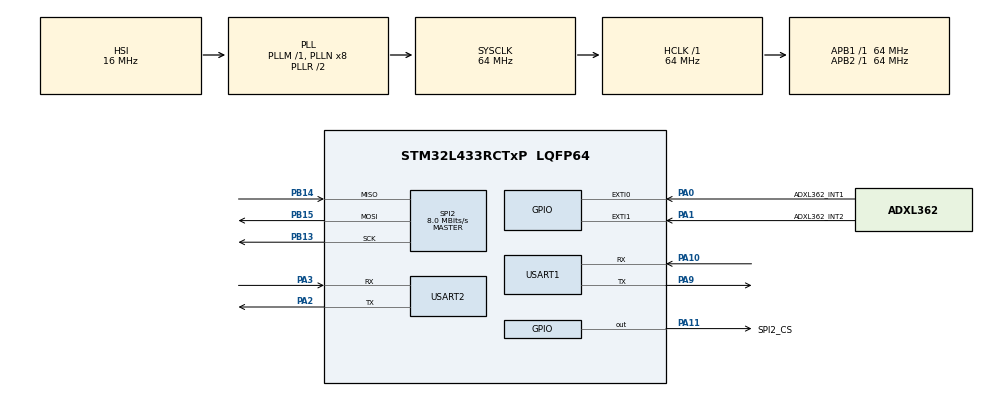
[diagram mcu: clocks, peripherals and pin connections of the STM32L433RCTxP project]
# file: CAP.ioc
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Dma.Request0=SPI2_TX
Dma.Request1=SPI2_RX
Dma.Request2=USART2_RX
Dma.Request3=USART2_TX
Dma.Request4=USART1_RX
Dma.Request5=USART1_TX
Dma.SPI2_RX.1.Direction=DMA_PERIPH_TO_MEMORY
Dma.SPI2_RX.1.Instance=DMA1_Channel4
Dma.SPI2_RX.1.MemDataAlignment=DMA_MDATAALIGN_BYTE
Dma.SPI2_RX.1.MemInc=DMA_MINC_ENABLE
Dma.SPI2_RX.1.Mode=DMA_NORMAL
Dma.SPI2_RX.1.PeriphDataAlignment=DMA_PDATAALIGN_BYTE
Dma.SPI2_RX.1.PeriphInc=DMA_PINC_DISABLE
Dma.SPI2_RX.1.Priority=DMA_PRIORITY_LOW
Dma.SPI2_TX.0.Direction=DMA_MEMORY_TO_PERIPH
Dma.SPI2_TX.0.Instance=DMA1_Channel5
Dma.SPI2_TX.0.MemDataAlignment=DMA_MDATAALIGN_BYTE
Dma.SPI2_TX.0.MemInc=DMA_MINC_ENABLE
Dma.SPI2_TX.0.Mode=DMA_NORMAL
Dma.SPI2_TX.0.PeriphDataAlignment=DMA_PDATAALIGN_BYTE
Dma.SPI2_TX.0.PeriphInc=DMA_PINC_DISABLE
Dma.SPI2_TX.0.Priority=DMA_PRIORITY_LOW
Dma.USART1_RX.4.Direction=DMA_PERIPH_TO_MEMORY
Dma.USART1_RX.4.Instance=DMA2_Channel7
Dma.USART1_RX.4.MemDataAlignment=DMA_MDATAALIGN_BYTE
Dma.USART1_RX.4.MemInc=DMA_MINC_ENABLE
Dma.USART1_RX.4.Mode=DMA_NORMAL
Dma.USART1_RX.4.PeriphDataAlignment=DMA_PDATAALIGN_BYTE
Dma.USART1_RX.4.PeriphInc=DMA_PINC_DISABLE
Dma.USART1_RX.4.Priority=DMA_PRIORITY_LOW
Dma.USART1_TX.5.Direction=DMA_MEMORY_TO_PERIPH
Dma.USART1_TX.5.Instance=DMA2_Channel6
Dma.USART1_TX.5.MemDataAlignment=DMA_MDATAALIGN_BYTE
Dma.USART1_TX.5.MemInc=DMA_MINC_ENABLE
Dma.USART1_TX.5.Mode=DMA_NORMAL
Dma.USART1_TX.5.PeriphDataAlignment=DMA_PDATAALIGN_BYTE
Dma.USART1_TX.5.PeriphInc=DMA_PINC_DISABLE
Dma.USART1_TX.5.Priority=DMA_PRIORITY_LOW
Dma.USART2_RX.2.Direction=DMA_PERIPH_TO_MEMORY
Dma.USART2_RX.2.Instance=DMA1_Channel6
Dma.USART2_RX.2.MemDataAlignment=DMA_MDATAALIGN_BYTE
Dma.USART2_RX.2.MemInc=DMA_MINC_ENABLE
Dma.USART2_RX.2.Mode=DMA_CIRCULAR
Dma.USART2_RX.2.PeriphDataAlignment=DMA_PDATAALIGN_BYTE
Dma.USART2_RX.2.PeriphInc=DMA_PINC_DISABLE
Dma.USART2_RX.2.Priority=DMA_PRIORITY_LOW
Dma.USART2_TX.3.Direction=DMA_MEMORY_TO_PERIPH
Dma.USART2_TX.3.Instance=DMA1_Channel7
Dma.USART2_TX.3.MemDataAlignment=DMA_MDATAALIGN_BYTE
Dma.USART2_TX.3.MemInc=DMA_MINC_ENABLE
Dma.USART2_TX.3.Mode=DMA_CIRCULAR
Dma.USART2_TX.3.PeriphDataAlignment=DMA_PDATAALIGN_BYTE
Dma.USART2_TX.3.PeriphInc=DMA_PINC_DISABLE
Dma.USART2_TX.3.Priority=DMA_PRIORITY_LOW
Mcu.Family=STM32L4
Mcu.Name=STM32L433RCTxP
Mcu.Package=LQFP64
NVIC.DMA1_Channel4_IRQn=true\:0\:0\:false\:false\:true\:false\:true
NVIC.DMA1_Channel5_IRQn=true\:0\:0\:false\:false\:true\:false\:true
NVIC.DMA1_Channel6_IRQn=true\:0\:0\:false\:false\:true\:false\:true
NVIC.DMA1_Channel7_IRQn=true\:0\:0\:false\:false\:true\:false\:true
NVIC.DMA2_Channel6_IRQn=true\:0\:0\:false\:false\:true\:false\:true
NVIC.DMA2_Channel7_IRQn=true\:0\:0\:false\:false\:true\:false\:true
NVIC.EXTI0_IRQn=true\:0\:0\:false\:false\:true\:true\:true
NVIC.EXTI1_IRQn=true\:0\:0\:false\:false\:true\:true\:true
NVIC.PriorityGroup=NVIC_PRIORITYGROUP_4
PA0.GPIO_Label=ADXL362_INT1
PA0.Signal=GPXTI0
PA1.GPIO_Label=ADXL362_INT2
PA1.Signal=GPXTI1
PA10.Mode=Asynchronous
PA10.Signal=USART1_RX
PA11.GPIO_Label=SPI2_CS
PA11.GPIO_Speed=GPIO_SPEED_FREQ_VERY_HIGH
PA11.PinState=GPIO_PIN_SET
PA11.Signal=GPIO_Output
PA13\ (JTMS-SWDIO).Mode=Serial_Wire
PA13\ (JTMS-SWDIO).Signal=SYS_JTMS-SWDIO
PA14\ (JTCK-SWCLK).Mode=Serial_Wire
PA14\ (JTCK-SWCLK).Signal=SYS_JTCK-SWCLK
PA2.Mode=Asynchronous
PA2.Signal=USART2_TX
PA3.Mode=Asynchronous
PA3.Signal=USART2_RX
PA9.Mode=Asynchronous
PA9.Signal=USART1_TX
PB13.Mode=Full_Duplex_Master
PB13.Signal=SPI2_SCK
PB14.Mode=Full_Duplex_Master
PB14.Signal=SPI2_MISO
PB15.Mode=Full_Duplex_Master
PB15.Signal=SPI2_MOSI
ProjectManager.HeapSize=0x200
ProjectManager.StackSize=0x400
ProjectManager.TargetToolchain=SW4STM32
RCC.ADCFreq_Value=64000000
RCC.AHBFreq_Value=64000000
RCC.APB1Freq_Value=64000000
RCC.APB1TimFreq_Value=64000000
RCC.APB2Freq_Value=64000000
RCC.APB2TimFreq_Value=64000000
RCC.CortexFreq_Value=64000000
RCC.HCLKFreq_Value=64000000
RCC.HSE_VALUE=8000000
RCC.HSI48_VALUE=48000000
RCC.HSI_VALUE=16000000
RCC.LSE_VALUE=32768
RCC.MSI_VALUE=4000000
RCC.PLLSourceVirtual=RCC_PLLSOURCE_HSI
RCC.PREFETCH_ENABLE=1
RCC.SYSCLKFreq_VALUE=64000000
RCC.SYSCLKSource=RCC_SYSCLKSOURCE_PLLCLK
RCC.USBFreq_Value=64000000
RCC.VCOOutputFreq_Value=128000000
SPI2.BaudRatePrescaler=SPI_BAUDRATEPRESCALER_8
SPI2.CalculateBaudRate=8.0 MBits/s
SPI2.DataSize=SPI_DATASIZE_8BIT
SPI2.Direction=SPI_DIRECTION_2LINES
SPI2.Mode=SPI_MODE_MASTER
SPI2.VirtualType=VM_MASTER
USART1.VirtualMode-Asynchronous=VM_ASYNC
USART2.VirtualMode-Asynchronous=VM_ASYNC
board=NUCLEO-L433RC-P

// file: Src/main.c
/* USER CODE BEGIN Header */
/**
  ******************************************************************************
  * @file           : main.c
  * @brief          : Main program body
  ******************************************************************************
  * @attention
  *
  * <h2><center>&copy; Copyright (c) 2019 STMicroelectronics.
  * All rights reserved.</center></h2>
  *
  * This software component is licensed by ST under BSD 3-Clause license,
  * the "License"; You may not use this file except in compliance with the
  * License. You may obtain a copy of the License at:
  *                        opensource.org/licenses/BSD-3-Clause
  *
  ******************************************************************************
  */
/* USER CODE END Header */

#include "main.h"

/* USER CODE BEGIN Includes */
#include "ADXL362.h"
/* USER CODE END Includes */

SPI_HandleTypeDef hspi2;
DMA_HandleTypeDef hdma_spi2_tx;
DMA_HandleTypeDef hdma_spi2_rx;

UART_HandleTypeDef huart1;
UART_HandleTypeDef huart2;
DMA_HandleTypeDef hdma_usart1_rx;
DMA_HandleTypeDef hdma_usart1_tx;
DMA_HandleTypeDef hdma_usart2_rx;
DMA_HandleTypeDef hdma_usart2_tx;

/* USER CODE BEGIN PV */
int8_t x8 = 0, y8 = 0, z8 = 0, temp8 = 0;
int16_t x12 = 0, y12 = 0, z12 = 0, temp12 = 0;
volatile uint32_t drFlag, GarageState;
//float xg, yg, zg;
char message[100];
/* USER CODE END PV */

void SystemClock_Config(void);
static void MX_GPIO_Init(void);
static void MX_DMA_Init(void);
static void MX_SPI2_Init(void);
static void MX_USART2_UART_Init(void);
static void MX_USART1_UART_Init(void);
/* USER CODE BEGIN PFP */
void HAL_SPI_TxRxCpltCallback(SPI_HandleTypeDef *hspi);
void HAL_GPIO_EXTI_Callback(uint16_t GPIO_Pin);
/* USER CODE END PFP */

/* USER CODE BEGIN 0 */
void HAL_SPI_TxRxCpltCallback(SPI_HandleTypeDef *hspi)
{
	if(hspi->Instance==SPI2)
	{
	}
}

void HAL_GPIO_EXTI_Callback(uint16_t GPIO_Pin)
{
	if(GPIO_Pin == ADXL362_INT1_Pin)
	{
		drFlag = 12;
	}
}

/* USER CODE END 0 */

int main(void)
{

  /* MCU Configuration--------------------------------------------------------*/

  /* Reset of all peripherals, Initializes the Flash interface and the Systick. */
  HAL_Init();

  /* Configure the system clock */
  SystemClock_Config();

  /* Initialize all configured peripherals */
  MX_GPIO_Init();
  MX_DMA_Init();
  MX_SPI2_Init();
  MX_USART2_UART_Init();
  MX_USART1_UART_Init();
  /* USER CODE BEGIN 2 */
  ADXL362_Init();
  /* USER CODE END 2 */

  /* Infinite loop */
  /* USER CODE BEGIN WHILE */
  while (1)
  {
	  if(drFlag == 8)
	  {
		  drFlag = 0;
		  ADXL362_GetXYZ8(&x8, &y8, &z8);
		  sprintf(message, "x = %+04d, y = %+04d, z = %+04d\r\n", x8, y8, z8);
		  HAL_UART_Transmit(&huart2, (uint8_t*)message, strlen(message), 0xFFFF);
	  }

	  else if(drFlag == 12)
	  {
		  drFlag = 0;
		  ADXL362_GetXYZT12(&x12, &y12, &z12, &temp12);
		  sprintf(message, "x = %+05d, y = %+05d, z = %+05d, temp = %+05d\r\n", x12, y12, z12, temp12);
		  //sprintf(message, "%04X, %04X, %04X\r\n", x12, y12, z12);
		  HAL_UART_Transmit(&huart2, (uint8_t*)message, strlen(message), 0xFFFF);
	  }
    /* USER CODE END WHILE */

  }
}

void SystemClock_Config(void)
{
  RCC_OscInitTypeDef RCC_OscInitStruct = {0};
  RCC_ClkInitTypeDef RCC_ClkInitStruct = {0};
  RCC_PeriphCLKInitTypeDef PeriphClkInit = {0};

  /** Initializes the CPU, AHB and APB busses clocks
  */
  RCC_OscInitStruct.OscillatorType = RCC_OSCILLATORTYPE_HSI;
  RCC_OscInitStruct.HSIState = RCC_HSI_ON;
  RCC_OscInitStruct.HSICalibrationValue = RCC_HSICALIBRATION_DEFAULT;
  RCC_OscInitStruct.PLL.PLLState = RCC_PLL_ON;
  RCC_OscInitStruct.PLL.PLLSource = RCC_PLLSOURCE_HSI;
  RCC_OscInitStruct.PLL.PLLM = 1;
  RCC_OscInitStruct.PLL.PLLN = 8;
  RCC_OscInitStruct.PLL.PLLP = RCC_PLLP_DIV7;
  RCC_OscInitStruct.PLL.PLLQ = RCC_PLLQ_DIV2;
  RCC_OscInitStruct.PLL.PLLR = RCC_PLLR_DIV2;
  if (HAL_RCC_OscConfig(&RCC_OscInitStruct) != HAL_OK)
  {
    Error_Handler();
  }
  /** Initializes the CPU, AHB and APB busses clocks
  */
  RCC_ClkInitStruct.ClockType = RCC_CLOCKTYPE_HCLK|RCC_CLOCKTYPE_SYSCLK
                              |RCC_CLOCKTYPE_PCLK1|RCC_CLOCKTYPE_PCLK2;
  RCC_ClkInitStruct.SYSCLKSource = RCC_SYSCLKSOURCE_PLLCLK;
  RCC_ClkInitStruct.AHBCLKDivider = RCC_SYSCLK_DIV1;
  RCC_ClkInitStruct.APB1CLKDivider = RCC_HCLK_DIV1;
  RCC_ClkInitStruct.APB2CLKDivider = RCC_HCLK_DIV1;

  if (HAL_RCC_ClockConfig(&RCC_ClkInitStruct, FLASH_LATENCY_3) != HAL_OK)
  {
    Error_Handler();
  }
  PeriphClkInit.PeriphClockSelection = RCC_PERIPHCLK_USART1|RCC_PERIPHCLK_USART2;
  PeriphClkInit.Usart1ClockSelection = RCC_USART1CLKSOURCE_PCLK2;
  PeriphClkInit.Usart2ClockSelection = RCC_USART2CLKSOURCE_PCLK1;
  if (HAL_RCCEx_PeriphCLKConfig(&PeriphClkInit) != HAL_OK)
  {
    Error_Handler();
  }
  /** Configure the main internal regulator output voltage
  */
  if (HAL_PWREx_ControlVoltageScaling(PWR_REGULATOR_VOLTAGE_SCALE1) != HAL_OK)
  {
    Error_Handler();
  }
}

static void MX_SPI2_Init(void)
{

  /* SPI2 parameter configuration*/
  hspi2.Instance = SPI2;
  hspi2.Init.Mode = SPI_MODE_MASTER;
  hspi2.Init.Direction = SPI_DIRECTION_2LINES;
  hspi2.Init.DataSize = SPI_DATASIZE_8BIT;
  hspi2.Init.CLKPolarity = SPI_POLARITY_LOW;
  hspi2.Init.CLKPhase = SPI_PHASE_1EDGE;
  hspi2.Init.NSS = SPI_NSS_SOFT;
  hspi2.Init.BaudRatePrescaler = SPI_BAUDRATEPRESCALER_8;
  hspi2.Init.FirstBit = SPI_FIRSTBIT_MSB;
  hspi2.Init.TIMode = SPI_TIMODE_DISABLE;
  hspi2.Init.CRCCalculation = SPI_CRCCALCULATION_DISABLE;
  hspi2.Init.CRCPolynomial = 7;
  hspi2.Init.CRCLength = SPI_CRC_LENGTH_DATASIZE;
  hspi2.Init.NSSPMode = SPI_NSS_PULSE_ENABLE;
  if (HAL_SPI_Init(&hspi2) != HAL_OK)
  {
    Error_Handler();
  }

}

static void MX_USART1_UART_Init(void)
{

  huart1.Instance = USART1;
  huart1.Init.BaudRate = 115200;
  huart1.Init.WordLength = UART_WORDLENGTH_8B;
  huart1.Init.StopBits = UART_STOPBITS_1;
  huart1.Init.Parity = UART_PARITY_NONE;
  huart1.Init.Mode = UART_MODE_TX_RX;
  huart1.Init.HwFlowCtl = UART_HWCONTROL_NONE;
  huart1.Init.OverSampling = UART_OVERSAMPLING_16;
  huart1.Init.OneBitSampling = UART_ONE_BIT_SAMPLE_DISABLE;
  huart1.AdvancedInit.AdvFeatureInit = UART_ADVFEATURE_NO_INIT;
  if (HAL_UART_Init(&huart1) != HAL_OK)
  {
    Error_Handler();
  }

}

static void MX_USART2_UART_Init(void)
{

  huart2.Instance = USART2;
  huart2.Init.BaudRate = 115200;
  huart2.Init.WordLength = UART_WORDLENGTH_8B;
  huart2.Init.StopBits = UART_STOPBITS_1;
  huart2.Init.Parity = UART_PARITY_NONE;
  huart2.Init.Mode = UART_MODE_TX_RX;
  huart2.Init.HwFlowCtl = UART_HWCONTROL_NONE;
  huart2.Init.OverSampling = UART_OVERSAMPLING_16;
  huart2.Init.OneBitSampling = UART_ONE_BIT_SAMPLE_DISABLE;
  huart2.AdvancedInit.AdvFeatureInit = UART_ADVFEATURE_NO_INIT;
  if (HAL_UART_Init(&huart2) != HAL_OK)
  {
    Error_Handler();
  }

}

static void MX_DMA_Init(void)
{

  /* DMA controller clock enable */
  __HAL_RCC_DMA1_CLK_ENABLE();
  __HAL_RCC_DMA2_CLK_ENABLE();

  /* DMA interrupt init */
  /* DMA1_Channel4_IRQn interrupt configuration */
  HAL_NVIC_SetPriority(DMA1_Channel4_IRQn, 0, 0);
  HAL_NVIC_EnableIRQ(DMA1_Channel4_IRQn);
  /* DMA1_Channel5_IRQn interrupt configuration */
  HAL_NVIC_SetPriority(DMA1_Channel5_IRQn, 0, 0);
  HAL_NVIC_EnableIRQ(DMA1_Channel5_IRQn);
  /* DMA1_Channel6_IRQn interrupt configuration */
  HAL_NVIC_SetPriority(DMA1_Channel6_IRQn, 0, 0);
  HAL_NVIC_EnableIRQ(DMA1_Channel6_IRQn);
  /* DMA1_Channel7_IRQn interrupt configuration */
  HAL_NVIC_SetPriority(DMA1_Channel7_IRQn, 0, 0);
  HAL_NVIC_EnableIRQ(DMA1_Channel7_IRQn);
  /* DMA2_Channel6_IRQn interrupt configuration */
  HAL_NVIC_SetPriority(DMA2_Channel6_IRQn, 0, 0);
  HAL_NVIC_EnableIRQ(DMA2_Channel6_IRQn);
  /* DMA2_Channel7_IRQn interrupt configuration */
  HAL_NVIC_SetPriority(DMA2_Channel7_IRQn, 0, 0);
  HAL_NVIC_EnableIRQ(DMA2_Channel7_IRQn);

}

static void MX_GPIO_Init(void)
{
  GPIO_InitTypeDef GPIO_InitStruct = {0};

  /* GPIO Ports Clock Enable */
  __HAL_RCC_GPIOC_CLK_ENABLE();
  __HAL_RCC_GPIOA_CLK_ENABLE();
  __HAL_RCC_GPIOB_CLK_ENABLE();

  /*Configure GPIO pin Output Level */
  HAL_GPIO_WritePin(ADXL362_CS_GPIO_Port, ADXL362_CS_Pin, GPIO_PIN_SET);

  /*Configure GPIO pins : ADXL362_INT1_Pin ADXL362_INT2_Pin */
  GPIO_InitStruct.Pin = ADXL362_INT1_Pin|ADXL362_INT2_Pin;
  GPIO_InitStruct.Mode = GPIO_MODE_IT_RISING;
  GPIO_InitStruct.Pull = GPIO_NOPULL;
  HAL_GPIO_Init(GPIOA, &GPIO_InitStruct);

  /*Configure GPIO pin : ADXL362_CS_Pin */
  GPIO_InitStruct.Pin = ADXL362_CS_Pin;
  GPIO_InitStruct.Mode = GPIO_MODE_OUTPUT_PP;
  GPIO_InitStruct.Pull = GPIO_NOPULL;
  GPIO_InitStruct.Speed = GPIO_SPEED_FREQ_VERY_HIGH;
  HAL_GPIO_Init(ADXL362_CS_GPIO_Port, &GPIO_InitStruct);

  /* EXTI interrupt init*/
  HAL_NVIC_SetPriority(EXTI0_IRQn, 0, 0);
  HAL_NVIC_EnableIRQ(EXTI0_IRQn);

  HAL_NVIC_SetPriority(EXTI1_IRQn, 0, 0);
  HAL_NVIC_EnableIRQ(EXTI1_IRQn);

}

void Error_Handler(void)
{
}

/************************ (C) COPYRIGHT STMicroelectronics *****END OF FILE****/
